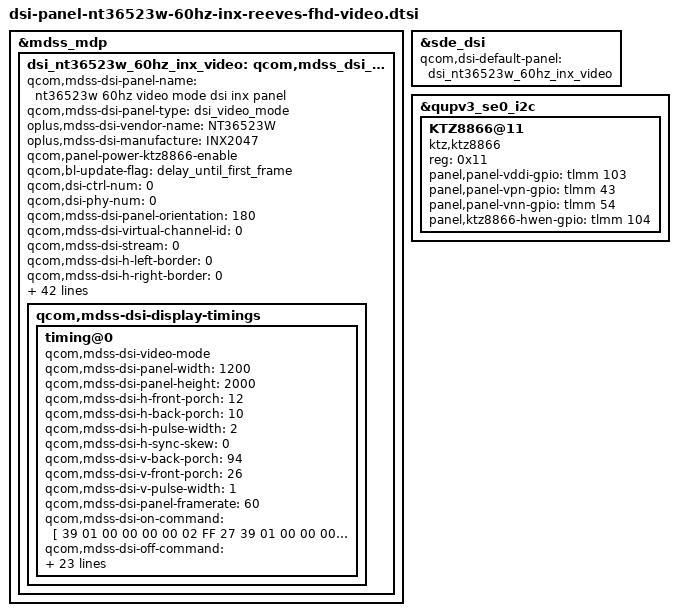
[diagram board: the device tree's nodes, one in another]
&mdss_mdp {
	dsi_nt36523w_60hz_inx_video: qcom,mdss_dsi_nt36523w_60hz_inx_video {
		qcom,mdss-dsi-panel-name =
			"nt36523w 60hz video mode dsi inx panel";
		qcom,mdss-dsi-panel-type = "dsi_video_mode";
		oplus,mdss-dsi-vendor-name = "NT36523W";
		oplus,mdss-dsi-manufacture = "INX2047";
		qcom,panel-power-ktz8866-enable;
		qcom,bl-update-flag = "delay_until_first_frame";

		qcom,dsi-ctrl-num = <0>;
		qcom,dsi-phy-num = <0>;
		qcom,mdss-dsi-panel-orientation = "180";
		qcom,mdss-dsi-virtual-channel-id = <0>;
		qcom,mdss-dsi-stream = <0>;
		qcom,mdss-dsi-h-left-border = <0>;
		qcom,mdss-dsi-h-right-border = <0>;
		qcom,mdss-dsi-v-top-border = <0>;
		qcom,mdss-dsi-v-bottom-border = <0>;
		qcom,mdss-dsi-bpp = <24>;
		qcom,mdss-dsi-color-order = "rgb_swap_rgb";
		qcom,mdss-dsi-underflow-color = <0xff>;
		qcom,mdss-dsi-border-color = <0>;
		qcom,mdss-dsi-h-sync-pulse = <0>;
		qcom,mdss-dsi-traffic-mode = "non_burst_sync_event";
		qcom,mdss-dsi-lane-map = "lane_map_0123";
		qcom,mdss-dsi-bllp-eof-power-mode;
		qcom,mdss-dsi-bllp-power-mode;
		qcom,mdss-dsi-tx-eot-append;
		qcom,mdss-dsi-lane-0-state;
		qcom,mdss-dsi-lane-1-state;
		qcom,mdss-dsi-lane-2-state;
		qcom,mdss-dsi-lane-3-state;
		qcom,mdss-dsi-dma-trigger = "trigger_sw";
		qcom,mdss-dsi-mdp-trigger = "none";
		qcom,mdss-dsi-lp11-init;
		qcom,mdss-dsi-incell-screen;
		qcom,mdss-dsi-bl-pmic-control-type = "bl_ctrl_external";
		qcom,mdss-dsi-reset-sequence = <1 10>, <0 10>, <1 10>, <0 10>, <1 10>;
		qcom,mdss-pan-physical-width-dimension = <135>;
		qcom,mdss-pan-physical-height-dimension = <226>;
		qcom,mdss-dsi-display-timings {
			timing@0 {
				qcom,mdss-dsi-video-mode;
				qcom,mdss-dsi-panel-width = <1200>;
				qcom,mdss-dsi-panel-height = <2000>;
				qcom,mdss-dsi-h-front-porch = <12>;
				qcom,mdss-dsi-h-back-porch = <10>;
				qcom,mdss-dsi-h-pulse-width = <2>;
				qcom,mdss-dsi-h-sync-skew = <0>;
				qcom,mdss-dsi-v-back-porch = <94>;
				qcom,mdss-dsi-v-front-porch = <26>;
				qcom,mdss-dsi-v-pulse-width = <1>;
				qcom,mdss-dsi-panel-framerate = <60>;
				qcom,mdss-dsi-on-command = [
					39 01 00 00 00 00 02 FF 27
					39 01 00 00 00 00 02 FB 01
					39 01 00 00 00 00 02 D0 31
					39 01 00 00 00 00 02 D1 88
					39 01 00 00 00 00 02 D2 30
					39 01 00 00 00 00 02 DE 43
					39 01 00 00 00 00 02 DF 02
					39 01 00 00 00 00 02 FF D0
					39 01 00 00 00 00 02 FB 01
					39 01 00 00 00 00 02 00 02
					39 01 00 00 00 00 02 FF 20
					39 01 00 00 00 00 02 FB 01
					39 01 00 00 00 00 02 05 D9
					39 01 00 00 00 00 02 0D 63
					39 01 00 00 00 00 02 0E 91
					39 01 00 00 00 00 02 0F 69
					39 01 00 00 00 00 02 07 7D
					39 01 00 00 00 00 02 08 5F
					39 01 00 00 00 00 02 0E 7D
					39 01 00 00 00 00 02 0F 7D
					39 01 00 00 00 00 02 95 F5
					39 01 00 00 00 00 02 96 F5
					39 01 00 00 00 00 02 9D 00
					39 01 00 00 00 00 02 9E 00
					39 01 00 00 00 00 02 44 51
					39 01 00 00 00 00 02 FF 20
					39 01 00 00 00 00 02 FB 01
					39 01 00 00 00 00 11 B0 00 00 00 1d 00 41 00 60 00 7a 00 91 00 a5 00 b8
					39 01 00 00 00 00 11 B1 00 c8 01 00 01 2a 01 6c 01 9f 01 ec 02 2b 02 2d
					39 01 00 00 00 00 11 B2 02 68 02 a9 02 d2 03 06 03 2a 03 53 03 5d 03 64
					39 01 00 00 00 00 0D B3 03 6a 03 76 03 80 03 8a 03 96 03 9a
					39 01 00 00 00 00 11 B4 00 00 00 1d 00 41 00 60 00 7a 00 91 00 a5 00 b8
					39 01 00 00 00 00 11 B5 00 c8 01 00 01 2a 01 6c 01 9f 01 ec 02 2b 02 2d
					39 01 00 00 00 00 11 B6 02 68 02 a9 02 d2 03 06 03 2a 03 53 03 5d 03 64
					39 01 00 00 00 00 0D B7 03 6a 03 76 03 80 03 8a 03 96 03 9a
					39 01 00 00 00 00 11 B8 00 00 00 1d 00 41 00 60 00 7a 00 91 00 a5 00 b8
					39 01 00 00 00 00 11 B9 00 c8 01 00 01 2a 01 6c 01 9f 01 ec 02 2b 02 2d
					39 01 00 00 00 00 11 BA 02 68 02 a9 02 d2 03 06 03 2a 03 53 03 5d 03 64
					39 01 00 00 00 00 0D BB 03 6a 03 76 03 80 03 8a 03 96 03 9a
					39 01 00 00 00 00 02 FF 21
					39 01 00 00 00 00 02 FB 01
					39 01 00 00 00 00 11 B0 00 00 00 1d 00 41 00 60 00 7a 00 91 00 a5 00 b8
					39 01 00 00 00 00 11 B1 00 c8 01 00 01 2a 01 6c 01 9f 01 ec 02 2b 02 2d
					39 01 00 00 00 00 11 B2 02 68 02 a9 02 d2 03 06 03 2a 03 53 03 61 03 74
					39 01 00 00 00 00 0D B3 03 8c 03 a3 03 c8 03 de 03 e6 03 e6
					39 01 00 00 00 00 11 B4 00 00 00 1d 00 41 00 60 00 7a 00 91 00 a5 00 b8
					39 01 00 00 00 00 11 B5 00 c8 01 00 01 2a 01 6c 01 9f 01 ec 02 2b 02 2d
					39 01 00 00 00 00 11 B6 02 68 02 a9 02 d2 03 06 03 2a 03 53 03 61 03 74
					39 01 00 00 00 00 0D B7 03 8c 03 a3 03 c8 03 de 03 e6 03 e6
					39 01 00 00 00 00 11 B8 00 00 00 1d 00 41 00 60 00 7a 00 91 00 a5 00 b8
					39 01 00 00 00 00 11 B9 00 c8 01 00 01 2a 01 6c 01 9f 01 ec 02 2b 02 2d
					39 01 00 00 00 00 11 BA 02 68 02 a9 02 d2 03 06 03 2a 03 53 03 61 03 74
					39 01 00 00 00 00 0D BB 03 8c 03 a3 03 c8 03 de 03 e6 03 e6
					39 01 00 00 00 00 02 FF 24
					39 01 00 00 00 00 02 FB 01
					39 01 00 00 00 00 02 91 44
					39 01 00 00 00 00 02 92 77
					39 01 00 00 00 00 02 93 1A
					39 01 00 00 00 00 02 94 40
					39 01 00 00 00 00 02 9A 08
					39 01 00 00 00 00 02 60 96
					39 01 00 00 00 00 02 61 D0
					39 01 00 00 00 00 02 63 70
					39 01 00 00 00 00 02 C2 C6
					39 01 00 00 00 00 02 9B 0F
					39 01 00 00 00 00 02 9A 08
					39 01 00 00 00 00 02 A5 00
					39 01 00 00 00 00 02 A6 41
					39 01 00 00 00 00 02 00 03
					39 01 00 00 00 00 02 01 03
					39 01 00 00 00 00 02 02 03
					39 01 00 00 00 00 02 03 03
					39 01 00 00 00 00 02 04 03
					39 01 00 00 00 00 02 05 03
					39 01 00 00 00 00 02 06 03
					39 01 00 00 00 00 02 07 03
					39 01 00 00 00 00 02 08 22
					39 01 00 00 00 00 02 09 08
					39 01 00 00 00 00 02 0A 05
					39 01 00 00 00 00 02 0B 1D
					39 01 00 00 00 00 02 0C 1C
					39 01 00 00 00 00 02 0D 11
					39 01 00 00 00 00 02 0E 10
					39 01 00 00 00 00 02 0F 0F
					39 01 00 00 00 00 02 10 0E
					39 01 00 00 00 00 02 11 0D
					39 01 00 00 00 00 02 12 0C
					39 01 00 00 00 00 02 13 04
					39 01 00 00 00 00 02 14 03
					39 01 00 00 00 00 02 15 03
					39 01 00 00 00 00 02 16 03
					39 01 00 00 00 00 02 17 03
					39 01 00 00 00 00 02 18 03
					39 01 00 00 00 00 02 19 03
					39 01 00 00 00 00 02 1A 03
					39 01 00 00 00 00 02 1B 03
					39 01 00 00 00 00 02 1C 03
					39 01 00 00 00 00 02 1D 03
					39 01 00 00 00 00 02 1E 22
					39 01 00 00 00 00 02 1F 08
					39 01 00 00 00 00 02 20 05
					39 01 00 00 00 00 02 21 1D
					39 01 00 00 00 00 02 22 1C
					39 01 00 00 00 00 02 23 11
					39 01 00 00 00 00 02 24 10
					39 01 00 00 00 00 02 25 0F
					39 01 00 00 00 00 02 26 0E
					39 01 00 00 00 00 02 27 0D
					39 01 00 00 00 00 02 28 0C
					39 01 00 00 00 00 02 29 04
					39 01 00 00 00 00 02 2A 03
					39 01 00 00 00 00 02 2B 03
					39 01 00 00 00 00 02 2F 05
					39 01 00 00 00 00 02 30 33
					39 01 00 00 00 00 02 31 40
					39 01 00 00 00 00 02 33 33
					39 01 00 00 00 00 02 34 05
					39 01 00 00 00 00 02 35 40
					39 01 00 00 00 00 02 37 55
					39 01 00 00 00 00 02 38 40
					39 01 00 00 00 00 02 39 00
					39 01 00 00 00 00 02 3A 51
					39 01 00 00 00 00 02 3B 3E
					39 01 00 00 00 00 02 3D 92
					39 01 00 00 00 00 02 AB 55
					39 01 00 00 00 00 02 AC 40
					39 01 00 00 00 00 02 3F 40
					39 01 00 00 00 00 02 43 40
					39 01 00 00 00 00 02 47 55
					39 01 00 00 00 00 02 4A 51
					39 01 00 00 00 00 02 4B 3E
					39 01 00 00 00 00 02 4C 91
					39 01 00 00 00 00 02 4D 21
					39 01 00 00 00 00 02 4E 43
					39 01 00 00 00 00 02 4F 65
					39 01 00 00 00 00 02 51 34
					39 01 00 00 00 00 02 52 12
					39 01 00 00 00 00 02 53 56
					39 01 00 00 00 00 03 55 84 04
					39 01 00 00 00 00 02 56 06
					39 01 00 00 00 00 02 58 21
					39 01 00 00 00 00 02 59 50
					39 01 00 00 00 00 02 5A 51
					39 01 00 00 00 00 02 5B 3E
					39 01 00 00 00 00 03 5E 00 0C
					39 01 00 00 00 00 02 5F 00
					39 01 00 00 00 00 02 7A FF
					39 01 00 00 00 00 02 7B FF
					39 01 00 00 00 00 02 7C 00
					39 01 00 00 00 00 02 7D 00
					39 01 00 00 00 00 02 7E 20
					39 01 00 00 00 00 02 7F 3C
					39 01 00 00 00 00 02 80 00
					39 01 00 00 00 00 02 81 00
					39 01 00 00 00 00 02 82 08
					39 01 00 00 00 00 02 97 02
					39 01 00 00 00 00 02 C5 10
					39 01 00 00 00 00 02 D7 55
					39 01 00 00 00 00 02 D8 55
					39 01 00 00 00 00 02 D9 23
					39 01 00 00 00 00 02 DA 05
					39 01 00 00 00 00 02 DB 01
					39 01 00 00 00 00 02 DC 77
					39 01 00 00 00 00 02 DD 55
					39 01 00 00 00 00 02 DE 27
					39 01 00 00 00 00 02 DF 01
					39 01 00 00 00 00 02 E0 77
					39 01 00 00 00 00 02 E1 01
					39 01 00 00 00 00 02 E2 77
					39 01 00 00 00 00 02 E3 01
					39 01 00 00 00 00 02 E4 77
					39 01 00 00 00 00 02 E5 01
					39 01 00 00 00 00 02 E6 77
					39 01 00 00 00 00 02 E7 00
					39 01 00 00 00 00 02 E8 00
					39 01 00 00 00 00 02 E9 01
					39 01 00 00 00 00 02 EA 77
					39 01 00 00 00 00 02 EB 01
					39 01 00 00 00 00 02 EE 77
					39 01 00 00 00 00 02 EF 01
					39 01 00 00 00 00 02 F0 77
					39 01 00 00 00 00 02 FF 25
					39 01 00 00 00 00 02 FB 01
					39 01 00 00 00 00 02 05 00
					39 01 00 00 00 00 02 F1 10
					39 01 00 00 00 00 02 1E 00
					39 01 00 00 00 00 02 1F 51
					39 01 00 00 00 00 02 20 3E
					39 01 00 00 00 00 02 25 00
					39 01 00 00 00 00 02 26 51
					39 01 00 00 00 00 02 27 3E
					39 01 00 00 00 00 02 3F 80
					39 01 00 00 00 00 02 40 00
					39 01 00 00 00 00 02 43 00
					39 01 00 00 00 00 02 44 51
					39 01 00 00 00 00 02 45 3E
					39 01 00 00 00 00 02 48 51
					39 01 00 00 00 00 02 49 3E
					39 01 00 00 00 00 02 5B 80
					39 01 00 00 00 00 02 5C 00
					39 01 00 00 00 00 02 5D 51
					39 01 00 00 00 00 02 5E 3E
					39 01 00 00 00 00 02 5F 51
					39 01 00 00 00 00 02 60 3E
					39 01 00 00 00 00 02 61 51
					39 01 00 00 00 00 02 62 3E
					39 01 00 00 00 00 02 68 0C
					39 01 00 00 00 00 02 FF 26
					39 01 00 00 00 00 02 FB 01
					39 01 00 00 00 00 02 00 A1
					39 01 00 00 00 00 02 02 31
					39 01 00 00 00 00 02 04 28
					39 01 00 00 00 00 02 06 30
					39 01 00 00 00 00 02 0C 13
					39 01 00 00 00 00 02 0D 0A
					39 01 00 00 00 00 02 0F 0A
					39 01 00 00 00 00 02 11 00
					39 01 00 00 00 00 02 12 50
					39 01 00 00 00 00 02 13 51
					39 01 00 00 00 00 02 14 65
					39 01 00 00 00 00 02 15 00
					39 01 00 00 00 00 02 16 10
					39 01 00 00 00 00 02 17 A0
					39 01 00 00 00 00 02 18 86
					39 01 00 00 00 00 02 22 00
					39 01 00 00 00 00 02 23 00
					39 01 00 00 00 00 02 19 0A
					39 01 00 00 00 00 02 1A A0
					39 01 00 00 00 00 02 1B 0A
					39 01 00 00 00 00 02 1C 00
					39 01 00 00 00 00 02 2A 0A
					39 01 00 00 00 00 02 2B A0
					39 01 00 00 00 00 02 1D 00
					39 01 00 00 00 00 02 1E 77
					39 01 00 00 00 00 02 1F 77
					39 01 00 00 00 00 02 2F 04
					39 01 00 00 00 00 02 30 77
					39 01 00 00 00 00 02 31 04
					39 01 00 00 00 00 02 32 97
					39 01 00 00 00 00 02 33 89
					39 01 00 00 00 00 02 34 67
					39 01 00 00 00 00 02 39 0C
					39 01 00 00 00 00 02 3A 74
					39 01 00 00 00 00 02 3B 06
					39 01 00 00 00 00 02 C8 04
					39 01 00 00 00 00 02 C9 8B
					39 01 00 00 00 00 02 CA 4E
					39 01 00 00 00 00 02 CB 00
					39 01 00 00 00 00 02 A9 50
					39 01 00 00 00 00 02 AA 4F
					39 01 00 00 00 00 02 AB 4E
					39 01 00 00 00 00 02 AC 4D
					39 01 00 00 00 00 02 AD 4C
					39 01 00 00 00 00 02 AE 4B
					39 01 00 00 00 00 02 AF 4A
					39 01 00 00 00 00 02 B0 49
					39 01 00 00 00 00 02 B1 47
					39 01 00 00 00 00 02 B2 45
					39 01 00 00 00 00 02 FF 27
					39 01 00 00 00 00 02 C0 18
					39 01 00 00 00 00 02 C1 00
					39 01 00 00 00 00 02 C2 00
					39 01 00 00 00 00 02 56 06
					39 01 00 00 00 00 02 58 80
					39 01 00 00 00 00 02 59 52
					39 01 00 00 00 00 02 5A 00
					39 01 00 00 00 00 02 5B 14
					39 01 00 00 00 00 02 5C 00
					39 01 00 00 00 00 02 5D 00
					39 01 00 00 00 00 02 5E 20
					39 01 00 00 00 00 02 5F 10
					39 01 00 00 00 00 02 60 00
					39 01 00 00 00 00 02 61 1B
					39 01 00 00 00 00 02 62 00
					39 01 00 00 00 00 02 63 01
					39 01 00 00 00 00 02 64 23
					39 01 00 00 00 00 02 65 1A
					39 01 00 00 00 00 02 66 00
					39 01 00 00 00 00 02 67 01
					39 01 00 00 00 00 02 68 23
					39 01 00 00 00 00 02 00 00
					39 01 00 00 00 00 02 C3 00
					39 01 00 00 00 00 02 98 01
					39 01 00 00 00 00 02 B4 03
					39 01 00 00 00 00 02 9B BE
					39 01 00 00 00 00 02 AB 14
					39 01 00 00 00 00 02 BC 08
					39 01 00 00 00 00 02 BD 28
					39 01 00 00 00 00 02 FF 2A
					39 01 00 00 00 00 02 FB 01
					39 01 00 00 00 00 02 22 2F
					39 01 00 00 00 00 02 23 08
					39 01 00 00 00 00 02 24 00
					39 01 00 00 00 00 02 25 76
					39 01 00 00 00 00 02 26 F8
					39 01 00 00 00 00 02 27 00
					39 01 00 00 00 00 02 28 1A
					39 01 00 00 00 00 02 29 00
					39 01 00 00 00 00 02 2A 1A
					39 01 00 00 00 00 02 2B 00
					39 01 00 00 00 00 02 2D 1A
					39 01 00 00 00 00 02 64 96
					39 01 00 00 00 00 02 65 00
					39 01 00 00 00 00 02 66 00
					39 01 00 00 00 00 02 6A 96
					39 01 00 00 00 00 02 6B 00
					39 01 00 00 00 00 02 6C 00
					39 01 00 00 00 00 02 70 92
					39 01 00 00 00 00 02 71 00
					39 01 00 00 00 00 02 72 00
					39 01 00 00 00 00 02 A2 33
					39 01 00 00 00 00 02 A3 30
					39 01 00 00 00 00 02 A4 C0
					39 01 00 00 00 00 02 E8 00
					39 01 00 00 00 00 02 97 3C
					39 01 00 00 00 00 02 98 02
					39 01 00 00 00 00 02 99 95
					39 01 00 00 00 00 02 9A 06
					39 01 00 00 00 00 02 9B 00
					39 01 00 00 00 00 02 9C 0B
					39 01 00 00 00 00 02 9D 0A
					39 01 00 00 00 00 02 9E 90
					39 01 00 00 00 00 02 FF 25
					39 01 00 00 00 00 02 13 02
					39 01 00 00 00 00 02 14 F2
					39 01 00 00 00 00 02 FF 25
					39 01 00 00 00 00 02 FB 01
					39 01 00 00 00 00 02 17 CF
					39 01 00 00 00 00 02 19 0F
					39 01 00 00 00 00 02 1B 5B
					39 01 00 00 00 00 02 FF F0
					39 01 00 00 00 00 02 FB 01
					39 01 00 00 00 00 02 3A 08
					39 01 00 00 00 00 02 FF D0
					39 01 00 00 00 00 02 FB 01
					39 01 00 00 00 00 02 02 AF
					39 01 00 00 00 00 02 09 FF
					39 01 00 00 00 00 02 FF 23
					39 01 00 00 00 00 02 FB 01
					39 01 00 00 00 00 02 00 68
					39 01 00 00 00 00 02 07 00
					39 01 00 00 00 00 02 08 01
					39 01 00 00 00 00 02 09 90
					39 01 00 00 00 00 02 FF 23
					39 01 00 00 00 00 02 FB 01
					39 01 00 00 00 00 02 10 0C
					39 01 00 00 00 00 02 11 02
					39 01 00 00 00 00 02 12 80
					39 01 00 00 00 00 02 15 83
					39 01 00 00 00 00 02 16 0C
					39 01 00 00 00 00 02 19 00
					39 01 00 00 00 00 02 1A 04
					39 01 00 00 00 00 02 1B 08
					39 01 00 00 00 00 02 1C 0C
					39 01 00 00 00 00 02 1D 10
					39 01 00 00 00 00 02 1E 14
					39 01 00 00 00 00 02 1F 18
					39 01 00 00 00 00 02 20 1C
					39 01 00 00 00 00 02 21 20
					39 01 00 00 00 00 02 22 24
					39 01 00 00 00 00 02 23 28
					39 01 00 00 00 00 02 24 2C
					39 01 00 00 00 00 02 25 30
					39 01 00 00 00 00 02 26 34
					39 01 00 00 00 00 02 27 38
					39 01 00 00 00 00 02 28 3C
					39 01 00 00 00 00 02 29 20
					39 01 00 00 00 00 02 2A 20
					39 01 00 00 00 00 02 2B 30
					39 01 00 00 00 00 02 30 FF
					39 01 00 00 00 00 02 31 FC
					39 01 00 00 00 00 02 32 FA
					39 01 00 00 00 00 02 33 F4
					39 01 00 00 00 00 02 34 F2
					39 01 00 00 00 00 02 35 F0
					39 01 00 00 00 00 02 36 EF
					39 01 00 00 00 00 02 37 EC
					39 01 00 00 00 00 02 38 EC
					39 01 00 00 00 00 02 39 E9
					39 01 00 00 00 00 02 3A E9
					39 01 00 00 00 00 02 3B E8
					39 01 00 00 00 00 02 3D E7
					39 01 00 00 00 00 02 3F E6
					39 01 00 00 00 00 02 40 E5
					39 01 00 00 00 00 02 41 E3
					39 01 00 00 00 00 02 58 FF
					39 01 00 00 00 00 02 59 FB
					39 01 00 00 00 00 02 5A EE
					39 01 00 00 00 00 02 5B E8
					39 01 00 00 00 00 02 5C E3
					39 01 00 00 00 00 02 5D DE
					39 01 00 00 00 00 02 5E D6
					39 01 00 00 00 00 02 5F D4
					39 01 00 00 00 00 02 60 D2
					39 01 00 00 00 00 02 61 D0
					39 01 00 00 00 00 02 62 CC
					39 01 00 00 00 00 02 63 CC
					39 01 00 00 00 00 02 64 CA
					39 01 00 00 00 00 02 65 C8
					39 01 00 00 00 00 02 66 C4
					39 01 00 00 00 00 02 67 C0
					39 01 00 00 00 00 02 FF 20
					39 01 00 00 00 00 02 FB 01
					39 01 00 00 00 00 0D C3 27 26 1E 20 19 18 17 16 15 13 07 03
					39 01 00 00 00 00 02 FF 10
					39 01 00 00 00 00 02 B9 01
					39 01 00 00 00 00 02 FF 20
					39 01 00 00 00 00 02 18 40
					39 01 00 00 00 00 02 FF 10
					39 01 00 00 00 00 02 B9 02
					39 01 00 00 00 00 02 FF 10
					39 01 00 00 00 00 02 FB 01
					39 01 00 00 00 00 02 B0 01
					39 01 00 00 00 00 02 35 00
					39 01 00 00 00 00 02 53 2C
					39 01 00 00 00 00 03 68 05 01
					39 01 00 00 00 00 06 3B 03 5F 1A 04 04
					05 01 00 00 64 00 02 11 00
					05 01 00 00 32 00 02 29 00];
				qcom,mdss-dsi-off-command = [
					05 01 00 00 14 00 02 28 00
					05 01 00 00 78 00 02 10 00];
				qcom,mdss-dsi-on-command-state = "dsi_lp_mode";
				qcom,mdss-dsi-off-command-state = "dsi_hs_mode";
				qcom,mdss-dsi-cabc-ui-command = [
					39 01 00 00 00 00 02 55 01
				];
				qcom,mdss-dsi-cabc-still-image-command = [
					39 01 00 00 00 00 02 55 02
				];
				qcom,mdss-dsi-cabc-video-command = [
					39 01 00 00 00 00 02 55 03
				];
				qcom,mdss-dsi-cabc-off-command = [
					39 01 00 00 00 00 02 55 00
				];
				qcom,mdss-dsi-cabc-ui-command-state = "dsi_lp_mode";
				qcom,mdss-dsi-cabc-still-image-command-state = "dsi_lp_mode";
				qcom,mdss-dsi-cabc-video-command-state = "dsi_lp_mode";
				qcom,mdss-dsi-cabc-off-command-state = "dsi_lp_mode";
			};
		};
	};
};

&dsi_nt36523w_60hz_inx_video {
	qcom,mdss-dsi-bl-pmic-control-type = "bl_ctrl_external";
	qcom,mdss-dsi-bl-min-level = <1>;
	qcom,mdss-dsi-bl-normal-max-level = <2047>;
	qcom,mdss-dsi-bl-max-level = <2047>;
	qcom,mdss-brightness-max-level = <2047>;
	qcom,mdss-brightness-min-level = <1>;
    qcom,mdss-brightness-normal-max-level = <2047>;
	qcom,mdss-brightness-default-level = <1600>;
	qcom,platform-reset-gpio = <&tlmm 82 0>;
};

&dsi_nt36523w_60hz_inx_video {
	qcom,esd-check-enabled;
	qcom,mdss-dsi-panel-status-check-mode = "check_esd_gpio";
	qcom,panel-master-esd-gpio = <&tlmm 81 0>;
	qcom,panel-slaves-esd-gpio = <&tlmm 97 0>;
	qcom,dsi-select-clocks = "mux_byte_clk0", "mux_pixel_clk0";
	qcom,mdss-dsi-display-timings {
		timing@0 {
			qcom,mdss-dsi-panel-phy-timings = [00 20 08 08 18 23 08
					08 08 02 04 00 1B 0D];
			qcom,display-topology = <1 0 1>;
			qcom,default-topology-index = <0>;
		};
	};
};

&sde_dsi {
	qcom,dsi-default-panel = <&dsi_nt36523w_60hz_inx_video>;
};

&qupv3_se0_i2c {
	KTZ8866@11 {
		compatible = "ktz,ktz8866";
		reg = <0x11>;
		panel,panel-vddi-gpio = <&tlmm 103 0>;
		panel,panel-vpn-gpio = <&tlmm 43 0>;
		panel,panel-vnn-gpio = <&tlmm 54 0>;
		panel,ktz8866-hwen-gpio = <&tlmm 104 0>;
	};
};
